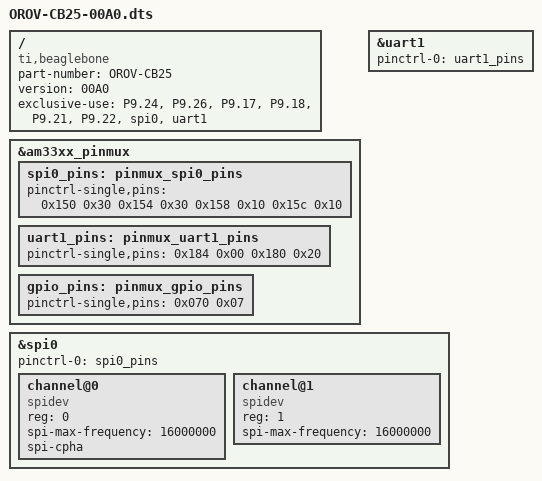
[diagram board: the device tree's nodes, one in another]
/dts-v1/;
/plugin/;

/ {
        compatible      = "ti,beaglebone", "ti,beaglebone-black";
        part-number     = "OROV-CB25";
        version         = "00A0";

        exclusive-use =
                /* Pins used by this overlay */
                /* "P9.11", */               /* ATMEGA RESET */
                "P9.24",                /* UART1 TXD */
                "P9.26",                /* UART1 RXD */
                "P9.17",                /* spi0_cs0 */
                "P9.18",                /* spi0_d1 */
                "P9.21",                /* spi0_d0 */
                "P9.22",                /* spi0_sclk */

                /* Hardware IP used */
                /* "gpio0_30", */
                "spi0",
                "uart1";

        fragment@0 {
                target = <&am33xx_pinmux>;
                __overlay__ {

                        spi0_pins: pinmux_spi0_pins {
                                pinctrl-single,pins = <
                                        0x150 0x30      /* spi0_sclk.spi0_sclk, INPUT_PULLUP | MODE0 */
                                        0x154 0x30      /* spi0_d0.spi0_d0, INPUT_PULLUP | MODE0 */
                                        0x158 0x10      /* spi0_d1.spi0_d1, OUTPUT_PULLUP | MODE0 */
                                        0x15c 0x10      /* spi0_cs0.spi0_cs0, OUTPUT_PULLUP | MODE0 */
                                >;
                        };

                        /* Configure UART1 */
                        uart1_pins: pinmux_uart1_pins {
                                pinctrl-single,pins = <
                                        0x184 0x00              /* P9_24 = uart1_txd.uart1_txd, OUTPUT Mode0 */
                                        0x180 0x20              /* P9_26 = uart1_rxd.uart1_rxd, INPUT  Mode0 */
                                >;
                        };

                        gpio_pins: pinmux_gpio_pins {
                                pinctrl-single,pins = <
                                        0x070 0x07              /* P9_11 GPIO0_30 | OUTPUT | Mode7 */
                                >;
                        };
                };
        };

        /*Turn on UART1*/
        fragment@1 {
                target =    <&uart1>; 
                __overlay__ {
                        status = "okay";
                        pinctrl-names = "default";
                        pinctrl-0 =    <&uart1_pins>;
                };
        };


        fragment@2 {
                target = <&spi0>;
                __overlay__ {
                        #address-cells = <1>;
                        #size-cells = <0>;

                        status = "okay";
                        pinctrl-names = "default";
                        pinctrl-0 = <&spi0_pins>;


                        channel@0 {
                                #address-cells = <1>;
                                #size-cells = <0>;

                                compatible = "spidev";

                                reg = <0>;
                                spi-max-frequency = <16000000>;
                                spi-cpha;
                        };


                        channel@1 {
                                #address-cells = <1>;
                                #size-cells = <0>;

                                compatible = "spidev";

                                reg = <1>;
                                spi-max-frequency = <16000000>;
                        };
                };
        };
	
	/*
        fragment@3 {
                target = <&ocp>;
                __overlay__ {
                        CB25_GPIO {
                                compatible = "gpio-of-helper";
                                status = "okay";
                                pinctrl-names = "default";
                                pinctrl-0 = <&gpio_pins>;

                                P9_11 {
                                        gpio-name = "ATMEGA_RESET";
                                        gpio = <&gpio0 30 0x00>;
                                        output;
                                        init-high;
                                };
                        };
                };
        };
*/
};
